# IWRL6432 register map
File version: 1.0
CPU: CM4 1.0, other endian, MPU, FPU, 3 interrupt priority bits
Registers are 32-bit, read-write, reset 0x0 unless marked. A register's access mark holds for its fields unless they carry their own. Offsets are from the block's base; [hi:lo] are bit positions.

## APP_LIN (part 1 of 2)
Base 0x53000000
0x00 SCIGCR0 — The SCIGCR0 register defines the module reset.
  [0] RESET — [0:0] This bit resets the SCI/LIN module. This bit is effective in LIN or SCI-compatible mode.. This bit affects the reset state of the SCI/LIN module. Writable Only in privilege mode
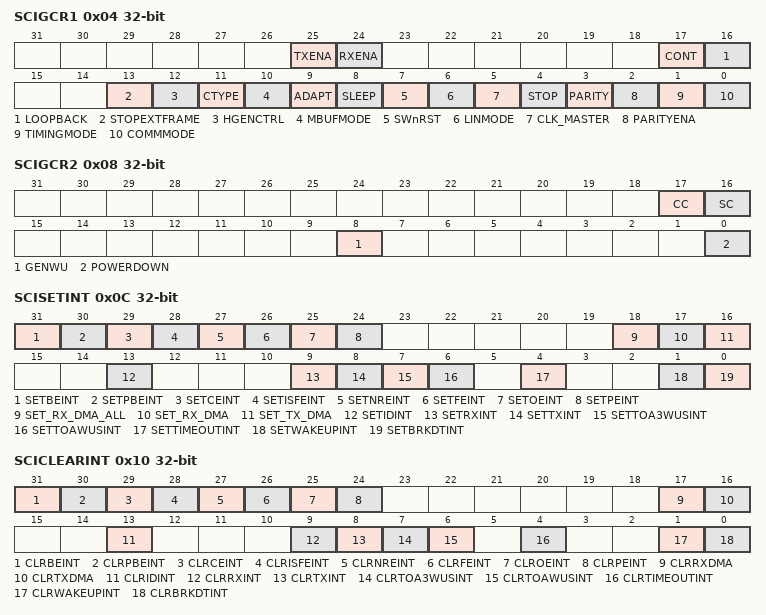
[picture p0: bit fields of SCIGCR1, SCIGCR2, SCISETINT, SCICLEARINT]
0x04 SCIGCR1 — The SCIGCR1 register defines the frame format, protocol, and communication mode used by the SCI.
  [25] TXENA — [25:25] Transmit enable. This bit is effective in LIN and SCI modes. Data is transferred from SCITD or the TDy (with y=0, 1,...7) buffers in LIN mode to the SCITXSHF shift out register only when the TXENA bit is set. Note: Data written to SCITD or the transmit multi-buffer before TXENA is set is not transmitted. If TXENA is cleared while transmission is ongoing, the data previously written to SCITD is sent (including the checksum byte in LIN mode).
  [24] RXENA — [24:24] Receive enable. This bit is effective in LIN or SCI-compatible mode. RXENA allows or prevents the transfer of data from SCIRXSHF to SCIRD or the receive multibuffers. Note: Clearing RXENA stops received characters from being transferred into the receive buffer or multi-buffers, prevents the RX status flags (see Table 7) from being updated by receive data, and inhibits both receive and error interrupts. However, the shift register continues to assemble data regardless of the state of RXENA. Note: If RXENA is cleared before the time the reception of a frame is complete, the data from the frame is not transferred into the receive buffer. Note: If RXENA is set before the time the reception of a frame is complete, the data from the frame is transferred into the receive buffer. If RXENA is set while SCIRXSHF is in the process of assembling a frame, the status flags are not guaranteed to be accurate for that frame. To ensure that the status flags correctly reflect what was detected on the bus during a particular frame, RXENA should be set before the detection of that frame
  [17] CONT — [17:17] Continue on suspend. This bit has an effect only when a program is being debugged with an emulator, and it determines how the SCI/LIN operates when the program is suspended. This bit affects the LIN counters. When this bit is set, the counters are not stopped during debug. When this bit is cleared, the counters are stopped during debug.
  [16] LOOPBACK — [16:16] Loopback bit. This bit is effective in LIN or SCI-compatible mode. The self-checking option for the SCI/LIN can be selected with this bit. If the LINTX and LINRX pins are configured with SCI/LIN functionality, then the LINTX pin is internally connected to the LINRX pin. Externally, during loop back operation, the LINTX pin outputs a high value and the LINRX pin is in a high-impedance state. If this bit value is changed while the SCI/LIN is transmitting or receiving data, errors may result.
  [13] STOPEXTFRAME — [13:13] Stop extended frame communication. This bit is effective in LIN mode only. This bit can be written only during extended frame communication. When the extended frame communication is stopped, this bit is cleared automatically.
  [12] HGENCTRL — [12:12] HGEN control bit. This bit is effective in LIN mode only. This bit controls the type of mask filtering comparison.
  [11] CTYPE — [11:11] Checksum type. This bit is effective in LIN mode only. This bit controls the type of checksum to be used: classic or enhanced.
  [10] MBUFMODE — [10:10] Multibuffer mode. This bit is effective in LIN or SCI-compatible mode. This bit controls receive/transmit buffer usage, that is, whether the RX/TX multibuffers are used or a single register, RD0/TD0, is used.
  [9] ADAPT — [9:9] Adapt mode enable. This mode is effective in LIN mode only. This bit has an effect during the detection of the Sync Field. There are two LIN protocol bit rate modes that could be enabled with this bit according to the Node capability file definition: automatic or select. Software and network configuration will decide which of the previous two modes. When this bit is cleared, the LIN 2.0 protocol fixed bit rate should be used. If the ADAPT bit is set, a LIN slave node detecting the baudrate will compare it to the prescalers in BRSR register and update it if they are different. The BRSR register will be updated with the new value. If this bit is not set there will be no adjustment to the BRSR register. This field is writable in LIN mode only.
  [8] SLEEP — [8:8] SCI sleep. SCI compatibility mode only. In a multiprocessor configuration, this bit controls the receive sleep function. Clearing this bit brings the SCI out of sleep mode. The receiver still operates when the SLEEP bit is set; however, RXRDY is updated and SCIRD is loaded with new data only when an address frame is detected. The remaining receiver status flags are updated and an error interrupt is requested if the corresponding interrupt enable bit is set, regardless of the value of the SLEEP bit. In this way, if an error is detected on the receive data line while the SCI is asleep, software can promptly deal with the error condition. The SLEEP bit is not automatically cleared when an address byte is detected. This field is writable in SCI mode only.
  [7] SWnRST — [7:7] Software reset (active low). This bit is effective in LIN or SCI-compatible mode. The SCI/LIN should only be configured while SWnRST = 0. Only the following configuration bits can be changed in runtime (i.e., while SWnRESET = 1): - STOP EXT Frame (SCIGCR1[13]) - CC bit (SCIGCR2[17]) - SC bit (SCIGCR2[16])
  [6] LINMODE — [6:6] LIN mode This bit controls the mode of operation of the module. Writable Only in privilege mode
  [5] CLK_MASTER — [5:5] SCI internal clock enable or LIN Master/Slave configuration. In the SCI mode, this bit enables the clock to the SCI module. In LIN mode, this bit determines whether a LIN node is a slave or master.
  [4] STOP — [4:4] SCI number of stop bits. This bit is effective in SCI-compatible mode only. Note: The receiver checks for only one stop bit. However in idle-line mode, the receiver waits until the end of the second stop bit (if STOP = 1) to begin checking for an idle period. This field is writable in SCI mode only.
  [3] PARITY — [3:3] SCI parity odd/even selection. This bit is effective in SCI-compatible mode only. If the PARITY ENA bit (SCIGCR1.2) is set, PARITY designates odd or even parity. The parity bit is calculated based on the data bits in each frame and the address bit (in address-bit mode). The start and stop fields in the frame are not included in the parity calculation. This field is writable in SCI mode only.
  [2] PARITYENA — [2:2] Parity enable. Enables or disables the parity function.
  [1] TIMINGMODE — [1:1] SCI timing mode bit. This bit is effective in SCI-compatible mode only. It must be set to 1 when the SCI mode is used. This bit configures the SCI for asynchronous operation.
  [0] COMMMODE — [0:0] SCI/LIN communication mode bit. In compatibility mode, it selects the SCI communication mode. In LIN mode it selects length control option for ID-field bits ID4 and ID5.
0x08 SCIGCR2 — The SCIGCR2 register is used to send or compare a checksum byte during extended frames, to generate a wakeup and for low-power mode control of the LIN module.
  [17] CC — [17:17] Compare Checksum. This mode is effective in LIN mode only. This bit is used by the receiver for extended frames to trigger a checksum compare. The user will initiate this transaction by writing a one to this bit. In non multibuffer mode, once the CC bit is set, the checksum will be compared on the byte that is currently being received, expected to be the checkbyte. During Multi-buffer mode, following are the scenarios associated with the CC bit : - If CC bit is set during the reception of the data, then the byte that is received after the reception of the programmed no. of data bytes indicated by SCIFORMAT[18:16], is treated as a checksum byte. - If CC bit is set during the IDLE period (i.e. during inter-frame space), then the next immediate byte will be treated as a checksum byte. A CE will immediatly be flagged if there is a checksum error. This bit is automatically cleared once the checksum is successfully compared.
  [16] SC — [16:16] Send Checksum This mode is effective in LIN mode only. This bit is used by the transmitter with extended frames to send a checkbyte. In non multibuffer mode the checkbyte will be sent after the current byte transmission. In multibuffer mode the checkbyte will be sent after the last byte count, indicated by the SCIFORMAT[18:16]). This field is writable in LIN mode only.
  [8] GENWU — [8:8] Generate wakeup signal. This bit controls the generation of a wakeup signal, by transmitting the TDO buffer value. This bit is cleared on reception of a valid sync break.
  [0] POWERDOWN — [0:0] Power down. This bit is effective in LIN or SCI-compatible mode. When the powerdown bit is set, the SCI/LIN module attempts to enter local low-power mode. If the POWERDOWN bit is set while the receiver is actively receiving data and the wakeup interrupt is disabled, then the SCI/LIN will delay low-power mode from being entered until completion of reception. In LIN mode the user may set the POWERDOWN bit on Sleep Command reception or on idle bus detection (more than 4 seconds, i.e. 80,000 cycles at 20kHz)
0x0C SCISETINT — The SCISETINT register is used to enable the various interrupts available in the LIN module.
  [31] SETBEINT — [31:31] Set bit error interrupt. This bit is effective in LIN mode only. Setting this bit enables the SCI/LIN module to generate an interrupt when there is a bit error. This field is writable in LIN mode only.
  [30] SETPBEINT — [30:30] Set physical bus error interrupt. This bit is effective in LIN mode only. Setting this bit enables the SCI/LIN module to generate an interrupt when a physical bus error occurs. This field is writable in LIN mode only.
  [29] SETCEINT — [29:29] Set checksum-error Interrupt. This bit is effective in LIN mode only. Setting this bit enables the SCI/LIN module to generate an interrupt when there is a checksum error. This field is writable in LIN mode only.
  [28] SETISFEINT — [28:28] Set inconsistent-sync-field-error interrupt. This bit is effective in LIN mode only. Setting this bit enables the SCI/LIN module to generate an interrupt when there is an inconsistent sync field error. This field is writable in LIN mode only.
  [27] SETNREINT — [27:27] Set no-response-error interrupt. This bit is effective in LIN mode only. Setting this bit enables the SCI/LIN module to generate an interrupt when a no-response error occurs. This field is writable in LIN mode only.
  [26] SETFEINT — [26:26] Set framing-error interrupt. This bit is effective in LIN or SCI-compatible mode. Setting this bit enables the SCI/LIN module to generate an interrupt when a framing error occurs.
  [25] SETOEINT — [25:25] Set overrun-error interrupt. This bit is effective in LIN or SCI-compatible mode. Setting this bit enables the SCI/LIN module to generate an interrupt when an overrun error occurs.
  [24] SETPEINT — [24:24] Set parity interrupt. This bit is effective in LIN or SCI-compatible mode. Setting this bit enables the SCI/LIN module to generate an interrupt when a parity error occurs.
  [18] SET_RX_DMA_ALL — [18:18] Set receiver DMA for Address & Data frames. This bit is effective in LIN or SCI-compatible mode. To enable RX DMA request for address and data frames this bit must be set. If it is cleared, RX interrupt request is generated for address frames and DMA requests are generated for data frames.
  [17] SET_RX_DMA — [17:17] Set receiver DMA. This bit is effective in LIN or SCI-compatible mode. To enable DMA requests for the receiver this bit must be set. If it is cleared, interrupt requests are generated depending on SETRXINT.
  [16] SET_TX_DMA — [16:16] Set transmit DMA. This bit is effective in LIN or SCI-compatible mode. To enable DMA requests for the transmitter, this bit must be set. If it is cleared, interrupt requests are generated depending on SETTXINT.
  [13] SETIDINT — [13:13] Set Identification interrupt. This bit is effective in LIN mode only. This bit is set to enable interrupt once a valid matching identifier is received.
  [9] SETRXINT — [9:9] Set Receiver interrupt. Setting this bit enables the SCI/LIN to generate a receive interrupt after a frame has been completely received and the data is being transferred from SCIRXSHF to SCIRD.
  [8] SETTXINT — [8:8] Set Transmitter interrupt. Setting this bit enables the SCI/LIN to generate a transmit interrupt as data is being transferred from SCITD to SCITXSHF and the TXRDY bit is being set.
  [7] SETTOA3WUSINT — [7:7] Set Timeout After 3 Wakeup Signals interrupt. This bit is effective in LIN mode only. Setting this bit enables the SCI/LIN to generate an interrupt when there is a timeout after 3 wakeup signals have been sent. This field is writable in LIN mode only.
  [6] SETTOAWUSINT — [6:6] Set Timeout After Wakeup Signal interrupt. This bit is effective in LIN mode only. Setting this bit enables the SCI/LIN to generate an interrupt when there is a timeout after one wakeup signal has been sent. This field is writable in LIN mode only.
  [4] SETTIMEOUTINT — [4:4] Set timeout interrupt. This bit is effective in LIN mode only. Setting this bit enables the SCI/LIN to generate an interrupt when no LIN bus activity (bus idle) occurs for at least 4 seconds. This field is writable in LIN mode only.
  [1] SETWAKEUPINT — [1:1] Set wake-up interrupt. This bit is effective in LIN or SCI-compatible mode. Setting this bit enables the SCI/LIN to generate a wake-up interrupt and thereby exit low-power mode. The wake-up interrupt is asserted on falling edge of the wake-up pulse. If enabled, the wake-up interrupt is asserted when local low-power mode is requested while the receiver is busy or if a low level is detected on the SCIRX pin during low-power mode. Wake-up interrupt is not asserted upon a wakeup pulse if the module is not in power down mode.
  [0] SETBRKDTINT — [0:0] Set break-detect interrupt. This bit is effective in SCI-compatible mode only. Setting this bit enables the SCI/LIN to generate an interrupt if a break condition is detected on the LINRX pin. This field is writable in SCI mode only.
0x10 SCICLEARINT — The SCICLEARINT register is used to disable the enabled interrupts without accessing the SCISETINT register.
  [31] CLRBEINT — [31:31] Clear Bit Error Interrupt. This bit is effective in LIN mode only. Setting this bit disables the bit error interrupt. This field is writable in LIN mode only.
  [30] CLRPBEINT — [30:30] Clear Physical Bus Error Interrupt. This bit is effective in LIN mode only. Setting this bit disables the physical-bus error interrupt. This field is writable in LIN mode only.
  [29] CLRCEINT — [29:29] Clear checksum-error Interrupt. This bit is effective in LIN mode only. Setting this bit disables the checksum-error interrupt. This field is writable in LIN mode only.
  [28] CLRISFEINT — [28:28] Clear Inconsistent-Sync-Field-Error Interrupt. This bit is effective in LIN mode only. Setting this bit disables the ISFE interrupt. This field is writable in LIN mode only.
  [27] CLRNREINT — [27:27] Clear No-Reponse-Error Interrupt. This bit is effective in LIN mode only. Setting this bit disables the no-response error interrupt. This field is writable in LIN mode only.
  [26] CLRFEINT — [26:26] Clear Framing-Error Interrupt. This bit is effective in LIN or SCI-compatible mode. Setting this bit disables framing-error interrupt.
  [25] CLROEINT — [25:25] Clear Overrun-Error Interrupt. This bit is effective in LIN or SCI-compatible mode. Setting this bit disables the overrun interrupt.
  [24] CLRPEINT — [24:24] Clear Parity Interrupt. This bit is effective in LIN or SCI-compatible mode. Setting this bit disables the parity error interrupt.
  [17] CLRRXDMA — [17:17] Clear receiver DMA. This bit is effective in LIN or SCI-compatible mode. Setting this bit disables the receive DMA request.
  [16] CLRTXDMA — [16:16] Clear transmit DMA. This bit is effective in LIN or SCI-compatible mode. Setting this bit disables the transmit DMA request.
  [13] CLRIDINT — [13:13] Clear Identifier interrupt. This bit is effective in LIN mode only. Setting this bit disables the ID interrupt.
  [9] CLRRXINT — [9:9] Clear Receiver interrupt. This bit is effective in LIN or SCI-compatible mode. Setting this bit disables the receiver interrupt.
  [8] CLRTXINT — [8:8] Clear Transmitter interrupt. This bit is effective in LIN or SCI-compatible mode. Setting this bit disables the transmitter interrupt.
  [7] CLRTOA3WUSINT — [7:7] Clear Timeout After 3 Wakeup Signals interrupt. This bit is effective in LIN mode only. Setting this bit disables the timeout after 3 wakeup signals interrupt. This field is writable in LIN mode only.
  [6] CLRTOAWUSINT — [6:6] Clear Timeout After Wakeup Signal interrupt. This bit is effective in LIN mode only. Setting this bit disables the timeout after one wakeup signal interrupt. This field is writable in LIN mode only.
  [4] CLRTIMEOUTINT — [4:4] Clear Timeout interrupt. This bit is effective in LIN mode only. Setting this bit disables the timeout (LIN bus idle) interrupt. This field is writable in LIN mode only.
  [1] CLRWAKEUPINT — [1:1] Clear Wake-up interrupt. This bit is effective in LIN or SCI-compatible mode. Setting this bit disables the wake-up interrupt.
  [0] CLRBRKDTINT — [0:0] Clear Break-detect interrupt. This bit is effective in SCI-compatible mode only. Setting this bit disables the Break-detect interrupt. This field is writable in SCI mode only.
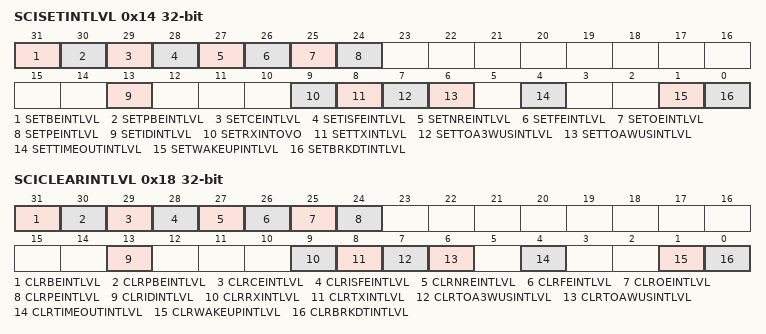
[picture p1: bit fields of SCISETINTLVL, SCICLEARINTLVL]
0x14 SCISETINTLVL — The SCISETINTLVL register is used to map individual interrupt sources to the INT1 interrupt line.
  [31] SETBEINTLVL — [31:31] Set Bit Error interrupt level. This bit is effective in LIN mode only. Writing to this bit maps the Bit Error interrupt level to the INT1 line. This field is writable in LIN mode only.
  [30] SETPBEINTLVL — [30:30] Set Physical Bus Error interrupt level. This bit is effective in LIN mode only. Writing to this bit maps the Physical Bus Error interrupt level to the INT1 line. This field is writable in LIN mode only.
  [29] SETCEINTLVL — [29:29] Set Checksum-error interrupt level. This bit is effective in LIN mode only. Writing to this bit maps the Checksum-error interrupt level to the INT1 line. This field is writable in LIN mode only.
  [28] SETISFEINTLVL — [28:28] Set Inconsistent-Sync-Field-Error interrupt level. This bit is effective in LIN mode only. Writing to this bit maps the Inconsistent-Sync-Field-Error interrupt level to the INT1 line. This field is writable in LIN mode only.
  [27] SETNREINTLVL — [27:27] Set No-Reponse-Error interrupt level. This bit is effective in LIN mode only. Writing to this bit maps the No-Response-Error interrupt level to the INT1 line. This field is writable in LIN mode only.
  [26] SETFEINTLVL — [26:26] Set Framing-Error interrupt level. This bit is effective in LIN or SCI-compatible mode. Writing to this bit maps the Framing-Error interrupt level to the INT1 line.
  [25] SETOEINTLVL — [25:25] Set Overrun-Error Interrupt Level. This bit is effective in LIN or SCI-compatible mode. Writing to this bit maps the Overrun-Error interrupt level to the INT1 line.
  [24] SETPEINTLVL — [24:24] Set Parity Error interrupt level. This bit is effective in LIN or SCI-compatible mode. Writing to this bit maps the Parity error interrupt level to the INT1 line.
  [13] SETIDINTLVL — [13:13] Set ID interrupt level. This bit is effective in LIN mode only. Writing to this bit maps the ID interrupt level to the INT1 line. This field is writable in LIN mode only.
  [9] SETRXINTOVO — [9:9] Set Receiver interrupt level. This bit is effective in LIN or SCI-compatible mode. Writing to this bit maps the receiver interrupt level to the INT1 line.
  [8] SETTXINTLVL — [8:8] Set Transmitter interrupt level. This bit is effective in LIN or SCI-compatible mode. Writing to this bit maps the transmitter interrupt level to the INT1 line.
  [7] SETTOA3WUSINTLVL — [7:7] Set Timeout After 3 Wakeup Signals interrupt level. This bit is effective in LIN mode only. Writing to this bit maps the timeout after 3 wakeup signals interrupt level to the INT1 line. This field is writable in LIN mode only.
  [6] SETTOAWUSINTLVL — [6:6] Set Timeout After Wakeup Signal interrupt level. This bit is effective in LIN mode only. Writing to this bit maps the the timeout after wakeup interrupt level to the INT1 line. This field is writable in LIN mode only.
  [4] SETTIMEOUTINTLVL — [4:4] Set Timeout interrupt level. This bit is effective in LIN mode only. Writing to this bit maps the timeout interrupt level to the INT1 line. This field is writable in LIN mode only.
  [1] SETWAKEUPINTLVL — [1:1] Set Wake-up interrupt level. This bit is effective in LIN or SCI-compatible mode. Writing to this bit maps the Wake-up interrupt level to the INT1 line.
  [0] SETBRKDTINTLVL — [0:0] Set Break-detect interrupt level. This bit is effective in SCI-compatible mode only. Writing to this bit maps the Break-detect interrupt level to the INT1 line. This field is writable in SCI mode only.
0x18 SCICLEARINTLVL — The SCICLEARINTLVL register is used to map individual interrupt sources to the INT0 line.
  [31] CLRBEINTLVL — [31:31] Clear Bit Error interrupt level. This bit is effective in LIN mode only. Writing to this bit maps the Bit Error interrupt level to the INT0 line. This field is writable in LIN mode only.
  [30] CLRPBEINTLVL — [30:30] Clear Physical Bus Error interrupt level. This bit is effective in LIN mode only. Writing to this bit maps the Physical Bus Error interrupt level to the INT0 line. This field is writable in LIN mode only.
  [29] CLRCEINTLVL — [29:29] Clear Checksum-error interrupt level. This bit is effective in LIN mode only. Writing to this bit maps the Checksum-error interrupt level to the INT0 line. This field is writable in LIN mode only.
  [28] CLRISFEINTLVL — [28:28] Clear Inconsistent-Sync-Field-Error interrupt level. This bit is effective in LIN mode only. Writing to this bit maps the Inconsistent-Sync-Field-Error interrupt level to the INT0 line. This field is writable in LIN mode only.
  [27] CLRNREINTLVL — [27:27] Clear No-Reponse-Error interrupt level. This bit is effective in LIN mode only. Writing to this bit maps the No-Response-Error interrupt level to the INT0 line. This field is writable in LIN mode only.
  [26] CLRFEINTLVL — [26:26] Clear Framing-Error interrupt level. This bit is effective in LIN or SCI-compatible mode. Writing to this bit maps the Framing-Error interrupt level to the INT0 line.
  [25] CLROEINTLVL — [25:25] Clear Overrun-Error Interrupt Level. This bit is effective in LIN or SCI-compatible mode. Writing to this bit maps the Overrun-Error interrupt level to the INT0 line.
  [24] CLRPEINTLVL — [24:24] Clear Parity Error interrupt level. This bit is effective in LIN or SCI-compatible mode. Writing to this bit maps the Parity Error interrupt level to the INT0 line.
  [13] CLRIDINTLVL — [13:13] Clear ID interrupt level. This bit is effective in LIN mode only. Writing to this bit maps the ID interrupt level to the INT0 line. This field is writable in LIN mode only.
  [9] CLRRXINTLVL — [9:9] Clear Receiver interrupt level. This bit is effective in LIN or SCI-compatible mode. Writing to this bit maps the receiver interrupt level to the INT0 line.
  [8] CLRTXINTLVL — [8:8] Clear Transmitter interrupt level. This bit is effective in LIN or SCI-compatible mode. Writing to this bit maps the transmitter interrupt level to the INT0 line.
  [7] CLRTOA3WUSINTLVL — [7:7] Clear Timeout After 3 Wakeup Signals interrupt level. This bit is effective in LIN mode only. Writing to this bit maps the timeout after 3 wakeup signals interrupt level to the INT0 line. This field is writable in LIN mode only.
  [6] CLRTOAWUSINTLVL — [6:6] Clear Timeout After Wakeup Signal interrupt level. This bit is effective in LIN mode only. Writing to this bit maps the the timeout after wakeup interrupt level to the INT0 line. This field is writable in LIN mode only.
  [4] CLRTIMEOUTINTLVL — [4:4] Clear Timeout interrupt level. This bit is effective in LIN mode only. Writing to this bit maps the timeout interrupt level to the INT0 line. This field is writable in LIN mode only.
  [1] CLRWAKEUPINTLVL — [1:1] Clear Wake-up interrupt level. This bit is effective in LIN or SCI-compatible mode. Writing to this bit maps the Wake-up interrupt level to the INT0 line.
  [0] CLRBRKDTINTLVL — [0:0] Clear Break-detect interrupt level. This bit is effective in SCI-compatible mode only. Writing to this bit maps the Break-detect interrupt level to the INT0 line. This field is writable in SCI mode only.
